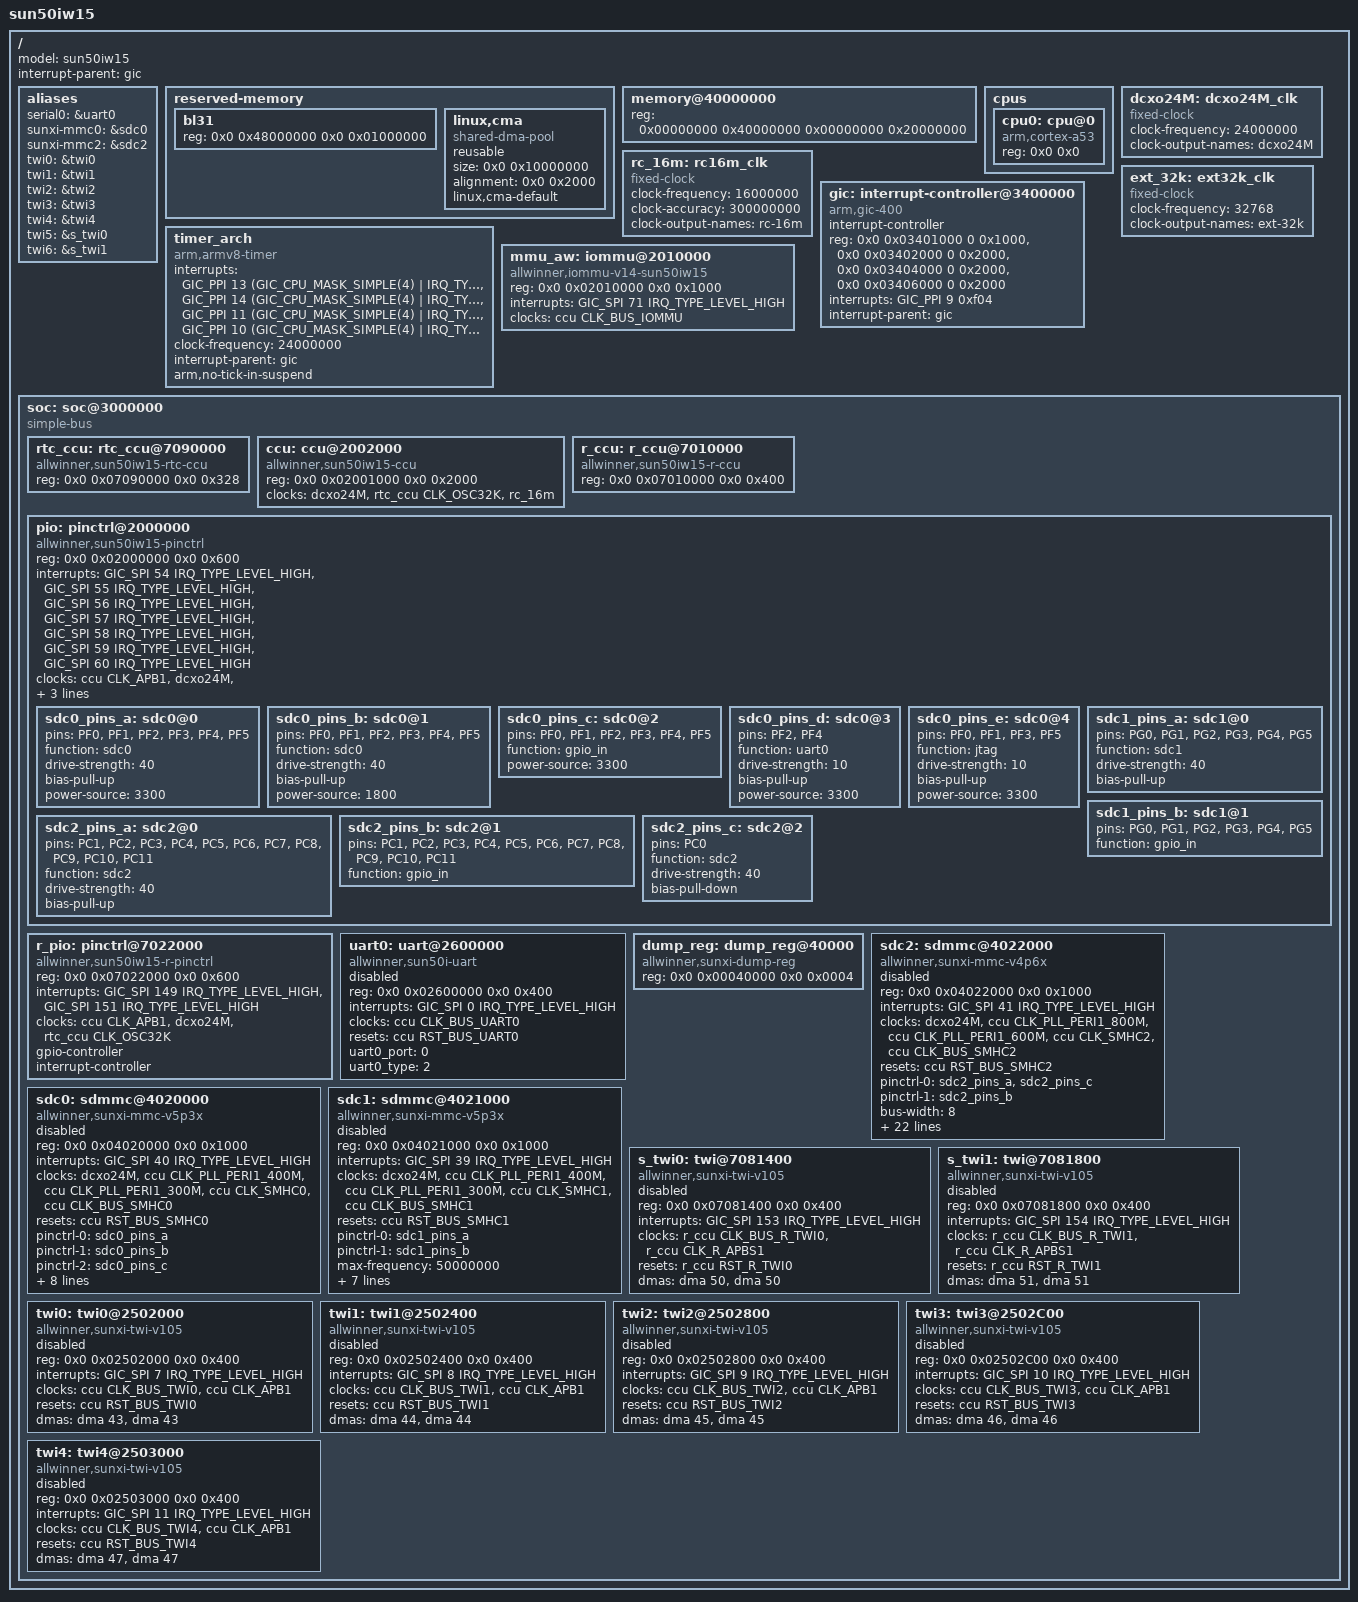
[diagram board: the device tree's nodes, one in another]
// SPDX-License-Identifier: (GPL-2.0+ or MIT)
#include <dt-bindings/clock/sun50iw15-ccu.h>
#include <dt-bindings/clock/sun50iw15-rtc.h>
#include <dt-bindings/clock/sun50iw15-r-ccu.h>
#include <dt-bindings/gpio/gpio.h>
#include <dt-bindings/gpio/sun4i-gpio.h>
#include <dt-bindings/interrupt-controller/arm-gic.h>
#include <dt-bindings/reset/sun50iw15-ccu.h>
#include <dt-bindings/reset/sun50iw15-r-ccu.h>
#include <dt-bindings/power/a523-power.h>
#include <dt-bindings/phy/phy.h>
#include <dt-bindings/thermal/thermal.h>

/ {
	model = "sun50iw15";
	interrupt-parent = <&gic>;
	#address-cells = <2>;
	#size-cells = <2>;

	aliases {
		serial0 = &uart0;
		sunxi-mmc0 = &sdc0;
		sunxi-mmc2 = &sdc2;
		twi0 = &twi0;
		twi1 = &twi1;
		twi2 = &twi2;
		twi3 = &twi3;
		twi4 = &twi4;
		twi5 = &s_twi0;
		twi6 = &s_twi1;
	};

	reserved-memory {
		#address-cells = <2>;
		#size-cells = <2>;
		ranges;

		bl31 {
			reg = <0x0 0x48000000 0x0 0x01000000>;
		};

		linux,cma {
			compatible = "shared-dma-pool";
			reusable;
			size = <0x0 0x10000000>;
			alignment = <0x0 0x2000>;
			linux,cma-default;
		};

	};

	/* avoid panic when memory-node err(from uboot) */
	memory@40000000 {
		device_type = "memory";
		reg = <0x00000000 0x40000000 0x00000000 0x20000000>;
	};

	cpus {
		#address-cells = <2>;
		#size-cells = <0>;

		cpu0: cpu@0 {
			device_type = "cpu";
			compatible = "arm,cortex-a53";
			reg = <0x0 0x0>;
		};
	};

	dcxo24M: dcxo24M_clk {
		#clock-cells = <0>;
		compatible = "fixed-clock";
		clock-frequency = <24000000>;
		clock-output-names = "dcxo24M";
	};

	rc_16m: rc16m_clk {
		#clock-cells = <0>;
		compatible = "fixed-clock";
		clock-frequency = <16000000>;
		clock-accuracy = <300000000>;
		clock-output-names = "rc-16m";
	};

	ext_32k: ext32k_clk {
		#clock-cells = <0>;
		compatible = "fixed-clock";
		clock-frequency = <32768>;
		clock-output-names = "ext-32k";
	};

	gic: interrupt-controller@3400000 {
		compatible = "arm,gic-400";
		#interrupt-cells = <3>;
		#address-cells = <0>;
		device_type = "gic";
		interrupt-controller;
		reg = <0x0 0x03401000 0 0x1000>, /* GIC Dist */
			  <0x0 0x03402000 0 0x2000>, /* GIC CPU */
			  <0x0 0x03404000 0 0x2000>, /* GIC VCPU Control */
			  <0x0 0x03406000 0 0x2000>; /* GIC VCPU */
		interrupts = <GIC_PPI 9 0xf04>;
		interrupt-parent = <&gic>;
	};

	timer_arch {
		compatible = "arm,armv8-timer";
		interrupts = <GIC_PPI 13 (GIC_CPU_MASK_SIMPLE(4) | IRQ_TYPE_LEVEL_LOW)>,
			   <GIC_PPI 14 (GIC_CPU_MASK_SIMPLE(4) | IRQ_TYPE_LEVEL_LOW)>,
			   <GIC_PPI 11 (GIC_CPU_MASK_SIMPLE(4) | IRQ_TYPE_LEVEL_LOW)>,
			   <GIC_PPI 10 (GIC_CPU_MASK_SIMPLE(4) | IRQ_TYPE_LEVEL_LOW)>;
		clock-frequency = <24000000>;
		interrupt-parent = <&gic>;
		arm,no-tick-in-suspend;
	};

	mmu_aw: iommu@2010000 {
		compatible = "allwinner,iommu-v14-sun50iw15";
		reg = <0x0 0x02010000 0x0 0x1000>;
		interrupts = <GIC_SPI 71 IRQ_TYPE_LEVEL_HIGH>;
		interrupt-names = "iommu-irq";
		clocks = <&ccu CLK_BUS_IOMMU>;
		clock-names = "iommu";
		/* clock-frequency = <24000000>; */
		#iommu-cells = <2>;
	};

	soc: soc@3000000 {
		compatible = "simple-bus";
		#address-cells = <2>;
		#size-cells = <2>;
		ranges;

		rtc_ccu: rtc_ccu@7090000 {
			compatible = "allwinner,sun50iw15-rtc-ccu";
			reg = <0x0 0x07090000 0x0 0x328>;
			#clock-cells = <1>;
			#reset-cells = <1>;
		};

		ccu: ccu@2002000 {
			compatible = "allwinner,sun50iw15-ccu";
			reg = <0x0 0x02001000 0x0 0x2000>;
			clocks = <&dcxo24M>, <&rtc_ccu CLK_OSC32K>, <&rc_16m>;
			clock-names = "hosc", "losc", "iosc";
			#clock-cells = <1>;
			#reset-cells = <1>;
		};

		r_ccu: r_ccu@7010000 {
			compatible = "allwinner,sun50iw15-r-ccu";
			reg = <0x0 0x07010000 0x0 0x400>;
			#clock-cells = <1>;
			#reset-cells = <1>;
		};

		pio: pinctrl@2000000 {
			//#address-cells = <1>;
			//#size-cells = <0>;
			compatible = "allwinner,sun50iw15-pinctrl";
			reg = <0x0 0x02000000 0x0 0x600>;
			interrupts = <GIC_SPI 54 IRQ_TYPE_LEVEL_HIGH>,
				     <GIC_SPI 55 IRQ_TYPE_LEVEL_HIGH>,
				     <GIC_SPI 56 IRQ_TYPE_LEVEL_HIGH>,
				     <GIC_SPI 57 IRQ_TYPE_LEVEL_HIGH>,
				     <GIC_SPI 58 IRQ_TYPE_LEVEL_HIGH>,
				     <GIC_SPI 59 IRQ_TYPE_LEVEL_HIGH>,
				     <GIC_SPI 60 IRQ_TYPE_LEVEL_HIGH>;
			clocks = <&ccu CLK_APB1>, <&dcxo24M>, <&rtc_ccu CLK_OSC32K>;
			clock-names = "apb", "hosc", "losc";
			gpio-controller;
			#gpio-cells = <3>;
			interrupt-controller;
			#interrupt-cells = <3>;

			sdc0_pins_a: sdc0@0 {
				pins = "PF0", "PF1", "PF2",
						"PF3", "PF4", "PF5";
				function = "sdc0";
				drive-strength = <40>;
				bias-pull-up;
				power-source = <3300>;
			};

			sdc0_pins_b: sdc0@1 {
				pins = "PF0", "PF1", "PF2",
						"PF3", "PF4", "PF5";
				function = "sdc0";
				drive-strength = <40>;
				bias-pull-up;
				power-source = <1800>;
			};

			sdc0_pins_c: sdc0@2 {
				pins = "PF0", "PF1", "PF2",
						"PF3", "PF4", "PF5";
				function = "gpio_in";
				power-source = <3300>;
			};

			/* TODO: add jtag pin */
			sdc0_pins_d: sdc0@3 {
				pins = "PF2", "PF4";
				function = "uart0";
				drive-strength = <10>;
				bias-pull-up;
				power-source = <3300>;
			};

			sdc0_pins_e: sdc0@4 {
				pins = "PF0", "PF1", "PF3",
						"PF5";
				function = "jtag";
				drive-strength = <10>;
				bias-pull-up;
				power-source = <3300>;
			};

			sdc1_pins_a: sdc1@0 {
				pins = "PG0", "PG1", "PG2",
						"PG3", "PG4", "PG5";
				function = "sdc1";
				drive-strength = <40>;
				bias-pull-up;
			};

			sdc1_pins_b: sdc1@1 {
				pins = "PG0", "PG1", "PG2",
						"PG3", "PG4", "PG5";
				function = "gpio_in";
			};

			sdc2_pins_a: sdc2@0 {
				pins = "PC1", "PC2", "PC3",
						"PC4", "PC5", "PC6", "PC7",
						"PC8", "PC9", "PC10", "PC11";
				function = "sdc2";
				drive-strength = <40>;
				bias-pull-up;
			};

			sdc2_pins_b: sdc2@1 {
				pins = "PC1", "PC2", "PC3",
						"PC4", "PC5", "PC6", "PC7",
						"PC8", "PC9", "PC10", "PC11";
				function = "gpio_in";
			};

			sdc2_pins_c: sdc2@2 {
				pins = "PC0";
				function = "sdc2";
				drive-strength = <40>;
				bias-pull-down;
			};
		};

		r_pio: pinctrl@7022000 {
			compatible = "allwinner,sun50iw15-r-pinctrl";
			reg = <0x0 0x07022000 0x0 0x600>;
			interrupts = <GIC_SPI 149 IRQ_TYPE_LEVEL_HIGH>,
				     <GIC_SPI 151 IRQ_TYPE_LEVEL_HIGH>;
			clocks = <&ccu CLK_APB1>, <&dcxo24M>, <&rtc_ccu CLK_OSC32K>;
			clock-names = "apb", "hosc", "losc";
			gpio-controller;
			#gpio-cells = <3>;
			interrupt-controller;
			#interrupt-cells = <3>;
		};

		uart0: uart@2600000 {
			compatible = "allwinner,sun50i-uart";
			reg = <0x0 0x02600000 0x0 0x400>;
			interrupts = <GIC_SPI 0 IRQ_TYPE_LEVEL_HIGH>;
			clocks = <&ccu CLK_BUS_UART0>;
			resets = <&ccu RST_BUS_UART0>;
			uart0_port = <0>;
			uart0_type = <2>;
			status = "disabled";
		};

		dump_reg: dump_reg@40000 {
			compatible = "allwinner,sunxi-dump-reg";
			reg = <0x0 0x00040000 0x0 0x0004>;
		};

		sdc2: sdmmc@4022000 {
			compatible = "allwinner,sunxi-mmc-v4p6x";
			device_type = "sdc2";
			reg = <0x0 0x04022000 0x0 0x1000>;
			interrupts = <GIC_SPI 41 IRQ_TYPE_LEVEL_HIGH>;
			clocks = <&dcxo24M>,
				<&ccu CLK_PLL_PERI1_800M>,
				<&ccu CLK_PLL_PERI1_600M>,
				<&ccu CLK_SMHC2>,
				<&ccu CLK_BUS_SMHC2>;
			clock-names = "osc24m","pll_periph","pll_periph_2","mmc","ahb";
			resets = <&ccu RST_BUS_SMHC2>;
			reset-names = "rst";
			pinctrl-names = "default","sleep";
			pinctrl-0 = <&sdc2_pins_a &sdc2_pins_c>;
			pinctrl-1 = <&sdc2_pins_b>;
			bus-width = <8>;
			req-page-count = <2>;
			cap-mmc-highspeed;
			cap-cmd23;
			mmc-cache-ctrl;
			non-removable;
			/*max-frequency = <200000000>;*/
			max-frequency = <50000000>;
			cap-erase;
			mmc-high-capacity-erase-size;
			no-sdio;
			no-sd;
			/*-- speed mode --*/
			/*sm0: DS26_SDR12*/
			/*sm1: HSSDR52_SDR25*/
			/*sm2: HSDDR52_DDR50*/
			/*sm3: HS200_SDR104*/
			/*sm4: HS400*/
			/*-- frequency point --*/
			/*f0: CLK_400K*/
			/*f1: CLK_25M*/
			/*f2: CLK_50M*/
			/*f3: CLK_100M*/
			/*f4: CLK_150M*/
			/*f5: CLK_200M*/

			sdc_tm4_sm0_freq0 = <0>;
			sdc_tm4_sm0_freq1 = <0>;
			sdc_tm4_sm1_freq0 = <0x00000000>;
			sdc_tm4_sm1_freq1 = <0>;
			sdc_tm4_sm2_freq0 = <0x00000000>;
			sdc_tm4_sm2_freq1 = <0>;
			sdc_tm4_sm3_freq0 = <0x05000000>;
			sdc_tm4_sm3_freq1 = <0x00000005>;
			sdc_tm4_sm4_freq0 = <0x00050000>;
			sdc_tm4_sm4_freq1 = <0x00000004>;
			sdc_tm4_sm4_freq0_cmd = <0>;
			sdc_tm4_sm4_freq1_cmd = <0>;

			/*vmmc-supply = <&reg_3p3v>;*/
			/*vqmc-supply = <&reg_3p3v>;*/
			/*vdmc-supply = <&reg_3p3v>;*/
			/*vmmc = "vcc-card";*/
			/*vqmc = "";*/
			/*vdmc = "";*/
			/*sunxi-power-save-mode;*/
			status = "disabled";
		};

		sdc0: sdmmc@4020000 {
			compatible = "allwinner,sunxi-mmc-v5p3x";
			device_type = "sdc0";
			reg = <0x0 0x04020000 0x0 0x1000>;
			interrupts = <GIC_SPI 40 IRQ_TYPE_LEVEL_HIGH>;
			clocks = <&dcxo24M>,
				 <&ccu CLK_PLL_PERI1_400M>,
				 <&ccu CLK_PLL_PERI1_300M>,
				 <&ccu CLK_SMHC0>,
				 <&ccu CLK_BUS_SMHC0>;
			clock-names = "osc24m","pll_periph","pll_periph_2","mmc","ahb";
			resets = <&ccu RST_BUS_SMHC0>;
			reset-names = "rst";
			pinctrl-names = "default","mmc_1v8","sleep","uart_jtag";
			pinctrl-0 = <&sdc0_pins_a>;
			pinctrl-1 = <&sdc0_pins_b>;
			pinctrl-2 = <&sdc0_pins_c>;
			pinctrl-3 = <&sdc0_pins_d &sdc0_pins_e>;
			max-frequency = <50000000>;
			bus-width = <4>;
			req-page-count = <2>;
			/*non-removable;*/
			/*broken-cd;*/
			/*cd-inverted*/
			/*cd-gpios = <&pio PF 6 GPIO_ACTIVE_LOW>;*/
			/* vmmc-supply = <&reg_3p3v>;*/
			/* vqmc-supply = <&reg_3p3v>;*/
			/* vdmc-supply = <&reg_3p3v>;*/
			/*vmmc = "vcc-card";*/
			/*vqmc = "";*/
			/*vdmc = "";*/
			cap-sd-highspeed;
			cap-wait-while-busy;
			no-sdio;
			no-mmc;
			/*sd-uhs-sdr50;*/
			/*sd-uhs-ddr50;*/
			/*cap-sdio-irq;*/
			/*keep-power-in-suspend;*/
			/*ignore-pm-notify;*/
			/*sunxi-power-save-mode;*/
			/*sunxi-dly-400k = <1 0 0 0>; */
			/*sunxi-dly-26M  = <1 0 0 0>;*/
			/*sunxi-dly-52M  = <1 0 0 0>;*/
			/*sunxi-dly-52M-ddr4  = <1 0 0 0>;*/
			/*sunxi-dly-52M-ddr8  = <1 0 0 0>;*/
			/*sunxi-dly-104M  = <1 0 0 0>;*/
			/*sunxi-dly-208M  = <1 0 0 0>;*/
			/*sunxi-dly-104M-ddr  = <1 0 0 0>;*/
			/*sunxi-dly-208M-ddr  = <1 0 0 0>;*/
			status = "disabled";
		};

		sdc1: sdmmc@4021000 {
			compatible = "allwinner,sunxi-mmc-v5p3x";
			device_type = "sdc1";
			reg = <0x0 0x04021000 0x0 0x1000>;
			interrupts = <GIC_SPI 39 IRQ_TYPE_LEVEL_HIGH>;
			clocks = <&dcxo24M>,
				 <&ccu CLK_PLL_PERI1_400M>,
				 <&ccu CLK_PLL_PERI1_300M>,
				 <&ccu CLK_SMHC1>,
				 <&ccu CLK_BUS_SMHC1>;
			clock-names = "osc24m","pll_periph","pll_periph_2","mmc","ahb";
			resets = <&ccu RST_BUS_SMHC1>;
			reset-names = "rst";
			pinctrl-names = "default","sleep";
			pinctrl-0 = <&sdc1_pins_a>;
			pinctrl-1 = <&sdc1_pins_b>;
			max-frequency = <50000000>;
			bus-width = <4>;
			/*broken-cd;*/
			/*cd-inverted*/
			/*cd-gpios = <&pio PG 6 6 1 2 0>;*/
			/* vmmc-supply = <&reg_3p3v>;*/
			/* vqmc-supply = <&reg_3p3v>;*/
			/* vdmc-supply = <&reg_3p3v>;*/
			/*vmmc = "vcc-card";*/
			/*vqmc = "";*/
			/*vdmc = "";*/
			cap-sd-highspeed;
			no-mmc;
			/*sd-uhs-sdr50;*/
			/*sd-uhs-ddr50;*/
			/*sd-uhs-sdr104;*/
			/*cap-sdio-irq;*/
			keep-power-in-suspend;
			/*ignore-pm-notify;*/
			/*sunxi-power-save-mode;*/
			/*sunxi-dly-400k = <1 0 0 0 0>; */
			/*sunxi-dly-26M  = <1 0 0 0 0>;*/
			/*sunxi-dly-52M  = <1 0 0 0 0>;*/
			sunxi-dly-52M-ddr4  = <1 0 0 0 2>;
			/*sunxi-dly-52M-ddr8  = <1 0 0 0 0>;*/
			sunxi-dly-104M  = <1 0 0 0 1>;
			/*sunxi-dly-208M  = <1 1 0 0 0>;*/
			sunxi-dly-208M  = <1 0 0 0 1>;
			/*sunxi-dly-104M-ddr  = <1 0 0 0 0>;*/
			/*sunxi-dly-208M-ddr  = <1 0 0 0 0>;*/
			status = "disabled";
		};

		s_twi0: twi@7081400 {
			#address-cells = <1>;
			#size-cells = <0>;
			compatible = "allwinner,sunxi-twi-v105";
			device_type = "s_twi0";
			reg = <0x0 0x07081400 0x0 0x400>;
			interrupts = <GIC_SPI 153 IRQ_TYPE_LEVEL_HIGH>;
			clocks = <&r_ccu CLK_BUS_R_TWI0>, <&r_ccu CLK_R_APBS1>;
			clock-names = "bus", "apb";
			resets = <&r_ccu RST_R_TWI0>;
			dmas = <&dma 50>, <&dma 50>;
			dma-names = "tx", "rx";
			status = "disabled";
		};

		s_twi1: twi@7081800 {
			#address-cells = <1>;
			#size-cells = <0>;
			compatible = "allwinner,sunxi-twi-v105";
			device_type = "s_twi1";
			reg = <0x0 0x07081800 0x0 0x400>;
			interrupts = <GIC_SPI 154 IRQ_TYPE_LEVEL_HIGH>;
			clocks = <&r_ccu CLK_BUS_R_TWI1>, <&r_ccu CLK_R_APBS1>;
			clock-names = "bus", "apb";
			resets = <&r_ccu RST_R_TWI1>;
			dmas = <&dma 51>, <&dma 51>;
			dma-names = "tx", "rx";
			status = "disabled";
		};

		twi0: twi0@2502000 {
			#address-cells = <1>;
			#size-cells = <0>;
			compatible = "allwinner,sunxi-twi-v105";
			device_type = "twi0";
			reg = <0x0 0x02502000 0x0 0x400>;
			interrupts = <GIC_SPI 7 IRQ_TYPE_LEVEL_HIGH>;
			clocks = <&ccu CLK_BUS_TWI0>, <&ccu CLK_APB1>;
			clock-names = "bus", "apb";
			resets = <&ccu RST_BUS_TWI0>;
			dmas = <&dma 43>, <&dma 43>;
			dma-names = "tx", "rx";
			status = "disabled";
		};

		twi1: twi1@2502400 {
			#address-cells = <1>;
			#size-cells = <0>;
			compatible = "allwinner,sunxi-twi-v105";
			device_type = "twi1";
			reg = <0x0 0x02502400 0x0 0x400>;
			interrupts = <GIC_SPI 8 IRQ_TYPE_LEVEL_HIGH>;
			clocks = <&ccu CLK_BUS_TWI1>, <&ccu CLK_APB1>;
			clock-names = "bus", "apb";
			resets = <&ccu RST_BUS_TWI1>;
			dmas = <&dma 44>, <&dma 44>;
			dma-names = "tx", "rx";
			status = "disabled";
		};

		twi2: twi2@2502800 {
			#address-cells = <1>;
			#size-cells = <0>;
			compatible = "allwinner,sunxi-twi-v105";
			device_type = "twi2";
			reg = <0x0 0x02502800 0x0 0x400>;
			interrupts = <GIC_SPI 9 IRQ_TYPE_LEVEL_HIGH>;
			clocks = <&ccu CLK_BUS_TWI2>, <&ccu CLK_APB1>;
			clock-names = "bus", "apb";
			resets = <&ccu RST_BUS_TWI2>;
			dmas = <&dma 45>, <&dma 45>;
			dma-names = "tx", "rx";
			status = "disabled";
		};

		twi3: twi3@2502C00 {
			#address-cells = <1>;
			#size-cells = <0>;
			compatible = "allwinner,sunxi-twi-v105";
			device_type = "twi3";
			reg = <0x0 0x02502C00 0x0 0x400>;
			interrupts = <GIC_SPI 10 IRQ_TYPE_LEVEL_HIGH>;
			clocks = <&ccu CLK_BUS_TWI3>, <&ccu CLK_APB1>;
			clock-names = "bus", "apb";
			resets = <&ccu RST_BUS_TWI3>;
			dmas = <&dma 46>, <&dma 46>;
			dma-names = "tx", "rx";
			status = "disabled";
		};

		twi4: twi4@2503000 {
			#address-cells = <1>;
			#size-cells = <0>;
			compatible = "allwinner,sunxi-twi-v105";
			device_type = "twi4";
			reg = <0x0 0x02503000 0x0 0x400>;
			interrupts = <GIC_SPI 11 IRQ_TYPE_LEVEL_HIGH>;
			clocks = <&ccu CLK_BUS_TWI4>, <&ccu CLK_APB1>;
			clock-names = "bus", "apb";
			resets = <&ccu RST_BUS_TWI4>;
			dmas = <&dma 47>, <&dma 47>;
			dma-names = "tx", "rx";
			status = "disabled";
		};
	};
};

